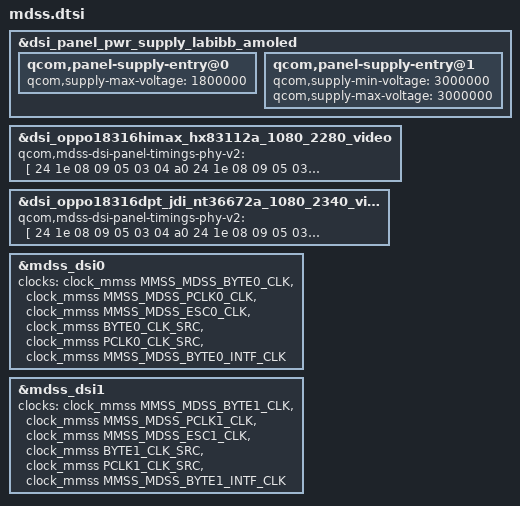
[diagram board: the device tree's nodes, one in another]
/* Copyright (c) 2019, The Linux Foundation. All rights reserved.
 *
 * This program is free software; you can redistribute it and/or modify
 * it under the terms of the GNU General Public License version 2 and
 * only version 2 as published by the Free Software Foundation.
 *
 * This program is distributed in the hope that it will be useful,
 * but WITHOUT ANY WARRANTY; without even the implied warranty of
 * MERCHANTABILITY or FITNESS FOR A PARTICULAR PURPOSE.  See the
 * GNU General Public License for more details.
 */

#include "dsi-panel-oppo18316himax_hx83112a_1080_2280_video.dtsi"
#include "dsi-panel-oppo18316dpt_jdi_nt36672a_1080_2340_video.dtsi"

/* diff with sdm660-mdss-panels.dtsi */
&dsi_panel_pwr_supply_labibb_amoled{
    qcom,panel-supply-entry@0 {
        qcom,supply-max-voltage = <1800000>;
    };

    qcom,panel-supply-entry@1 {
        qcom,supply-min-voltage = <3000000>;
        qcom,supply-max-voltage = <3000000>;
    };

    /delete-node/ qcom,panel-supply-entry@2;
    /delete-node/ qcom,panel-supply-entry@3;
    /delete-node/ qcom,panel-supply-entry@4;
};

&dsi_oppo18316himax_hx83112a_1080_2280_video {
	qcom,mdss-dsi-panel-timings-phy-v2 = [
		24 1e 08 09 05 03 04 a0
		24 1e 08 09 05 03 04 a0
		24 1e 08 09 05 03 04 a0
		24 1e 08 09 05 03 04 a0
		24 1a 08 09 05 03 04 a0];
};

&dsi_oppo18316dpt_jdi_nt36672a_1080_2340_video {
	qcom,mdss-dsi-panel-timings-phy-v2 = [
		24 1e 08 09 05 03 04 a0
		24 1e 08 09 05 03 04 a0
		24 1e 08 09 05 03 04 a0
		24 1e 08 09 05 03 04 a0
		24 1a 08 09 05 03 04 a0];
};

/* diff with sdm660-mdss.dtsi */
&mdss_dsi0{
    /delete-property/ wqhd-vddio-supply;

    clocks = <&clock_mmss MMSS_MDSS_BYTE0_CLK>,
             <&clock_mmss MMSS_MDSS_PCLK0_CLK>,
             <&clock_mmss MMSS_MDSS_ESC0_CLK>,
             <&clock_mmss BYTE0_CLK_SRC>,
             <&clock_mmss PCLK0_CLK_SRC>,
             <&clock_mmss MMSS_MDSS_BYTE0_INTF_CLK>;
    clock-names = "byte_clk", "pixel_clk", "core_clk",
        "byte_clk_rcg", "pixel_clk_rcg",
        "byte_intf_clk";
};

&mdss_dsi1{
    /delete-property/ wqhd-vddio-supply;

    clocks = <&clock_mmss MMSS_MDSS_BYTE1_CLK>,
             <&clock_mmss MMSS_MDSS_PCLK1_CLK>,
             <&clock_mmss MMSS_MDSS_ESC1_CLK>,
             <&clock_mmss BYTE1_CLK_SRC>,
             <&clock_mmss PCLK1_CLK_SRC>,
             <&clock_mmss MMSS_MDSS_BYTE1_INTF_CLK>;
    clock-names = "byte_clk", "pixel_clk", "core_clk",
        "byte_clk_rcg", "pixel_clk_rcg",
        "byte_intf_clk";
};
